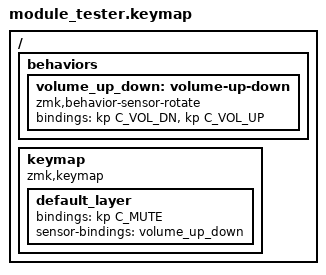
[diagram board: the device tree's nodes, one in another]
#include <behaviors.dtsi>
#include <dt-bindings/zmk/keys.h>
#include <dt-bindings/zmk/backlight.h>

/ {
    behaviors {
        volume_up_down: volume-up-down {
            compatible = "zmk,behavior-sensor-rotate";
            #sensor-binding-cells = <0>;
            bindings = <&kp C_VOL_DN>, <&kp C_VOL_UP>;
        };
    };

    keymap {
        compatible = "zmk,keymap";

        default_layer {
            // bindings = <&bl BL_CYCLE>; // <- LED
            bindings = <&kp C_MUTE>; //<- ENCODER
            sensor-bindings = <&volume_up_down>;
        };
    };
};
